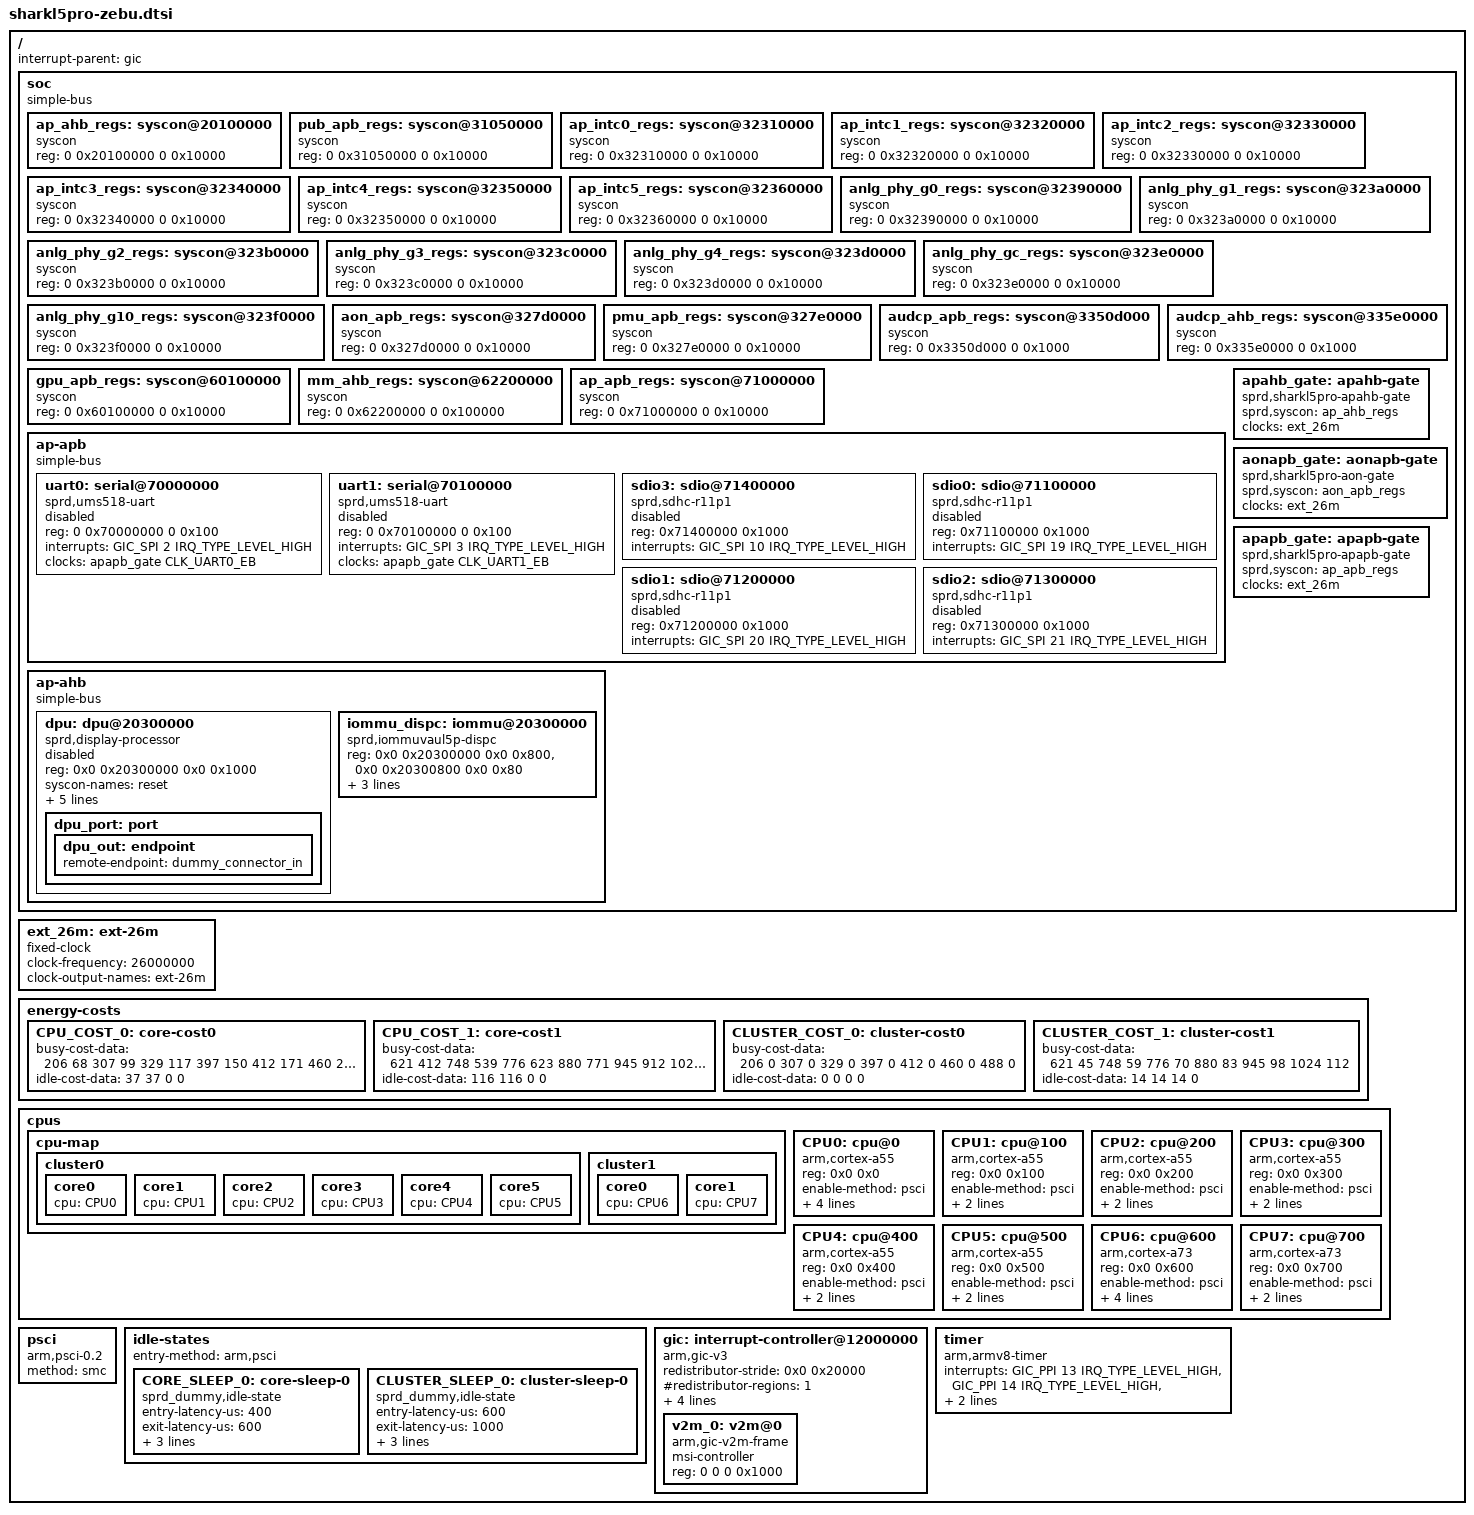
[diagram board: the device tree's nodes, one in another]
// SPDX-License-Identifier: (GPL-2.0+ OR MIT)
/*
 * Unisoc Sharkl5Pro platform DTS file
 *
 * Copyright (C) 2018, Unisoc Communications Inc.
 */

#include <dt-bindings/soc/sprd,sharkl5pro-regs.h>
#include <dt-bindings/soc/sprd,sharkl5pro-mask.h>
#include <dt-bindings/clock/sprd,sharkl5pro-clk.h>
#include <dt-bindings/interrupt-controller/arm-gic.h>

/ {
	interrupt-parent = <&gic>;
	#address-cells = <2>;
	#size-cells = <2>;

	soc: soc {
		compatible = "simple-bus";
		#address-cells = <2>;
		#size-cells = <2>;
		ranges;

		ap_ahb_regs: syscon@20100000 {
			compatible = "syscon";
			#syscon-cells = <2>;
			reg = <0 0x20100000 0 0x10000>;
		};

		pub_apb_regs: syscon@31050000 {
			compatible = "syscon";
			#syscon-cells = <2>;
			reg = <0 0x31050000 0 0x10000>;
		};

		ap_intc0_regs: syscon@32310000 {
			compatible = "syscon";
			#syscon-cells = <2>;
			reg = <0 0x32310000 0 0x10000>;
		};

		ap_intc1_regs: syscon@32320000 {
			compatible = "syscon";
			#syscon-cells = <2>;
			reg = <0 0x32320000 0 0x10000>;
		};

		ap_intc2_regs: syscon@32330000 {
			compatible = "syscon";
			#syscon-cells = <2>;
			reg = <0 0x32330000 0 0x10000>;
		};

		ap_intc3_regs: syscon@32340000 {
			compatible = "syscon";
			#syscon-cells = <2>;
			reg = <0 0x32340000 0 0x10000>;
		};

		ap_intc4_regs: syscon@32350000 {
			compatible = "syscon";
			#syscon-cells = <2>;
			reg = <0 0x32350000 0 0x10000>;
		};

		ap_intc5_regs: syscon@32360000 {
			compatible = "syscon";
			#syscon-cells = <2>;
			reg = <0 0x32360000 0 0x10000>;
		};

		anlg_phy_g0_regs: syscon@32390000 {
			compatible = "syscon";
			#syscon-cells = <2>;
			reg = <0 0x32390000 0 0x10000>;
		};

		anlg_phy_g1_regs: syscon@323a0000 {
			compatible = "syscon";
			#syscon-cells = <2>;
			reg = <0 0x323a0000 0 0x10000>;
		};

		anlg_phy_g2_regs: syscon@323b0000 {
			compatible = "syscon";
			#syscon-cells = <2>;
			reg = <0 0x323b0000 0 0x10000>;
		};

		anlg_phy_g3_regs: syscon@323c0000 {
			compatible = "syscon";
			#syscon-cells = <2>;
			reg = <0 0x323c0000 0 0x10000>;
		};

		anlg_phy_g4_regs: syscon@323d0000 {
			compatible = "syscon";
			#syscon-cells = <2>;
			reg = <0 0x323d0000 0 0x10000>;
		};

		anlg_phy_gc_regs: syscon@323e0000 {
			compatible = "syscon";
			#syscon-cells = <2>;
			reg = <0 0x323e0000 0 0x10000>;
		};

		anlg_phy_g10_regs: syscon@323f0000 {
			compatible = "syscon";
			#syscon-cells = <2>;
			reg = <0 0x323f0000 0 0x10000>;
		};

		aon_apb_regs: syscon@327d0000 {
			compatible = "syscon";
			#syscon-cells = <2>;
			reg = <0 0x327d0000 0 0x10000>;
		};

		pmu_apb_regs: syscon@327e0000 {
			compatible = "syscon";
			#syscon-cells = <2>;
			reg = <0 0x327e0000 0 0x10000>;
		};

		audcp_apb_regs: syscon@3350d000 {
			compatible = "syscon";
			#syscon-cells = <2>;
			reg = <0 0x3350d000 0 0x1000>;
		};

		audcp_ahb_regs: syscon@335e0000 {
			compatible = "syscon";
			#syscon-cells = <2>;
			reg = <0 0x335e0000 0 0x1000>;
		};

		gpu_apb_regs: syscon@60100000 {
			compatible = "syscon";
			#syscon-cells = <2>;
			reg = <0 0x60100000 0 0x10000>;
		};

		mm_ahb_regs: syscon@62200000 {
			compatible = "syscon";
			#syscon-cells = <2>;
			reg = <0 0x62200000 0 0x100000>;
		};

		ap_apb_regs: syscon@71000000 {
			compatible = "syscon";
			#syscon-cells = <2>;
			reg = <0 0x71000000 0 0x10000>;
		};

		ap-apb {
			compatible = "simple-bus";
			#address-cells = <2>;
			#size-cells = <2>;
			ranges;

			uart0: serial@70000000 {
				compatible = "sprd,ums518-uart",
					     "sprd,sc9836-uart";
				reg = <0 0x70000000 0 0x100>;
				interrupts = <GIC_SPI 2 IRQ_TYPE_LEVEL_HIGH>;
				clock-names = "enable", "uart", "source";
				clocks = <&apapb_gate CLK_UART0_EB>;
				status = "disabled";
			};

			uart1: serial@70100000 {
				compatible = "sprd,ums518-uart",
					     "sprd,sc9836-uart";
				reg = <0 0x70100000 0 0x100>;
				interrupts = <GIC_SPI 3 IRQ_TYPE_LEVEL_HIGH>;
				clock-names = "enable", "uart", "source";
				clocks = <&apapb_gate CLK_UART1_EB>;
				status = "disabled";
			};

			sdio3: sdio@71400000 {
				compatible = "sprd,sdhc-r11p1";
				reg = <0x71400000  0x1000>;
				interrupts = <GIC_SPI 10 IRQ_TYPE_LEVEL_HIGH>;
				status = "disabled";
			};

			sdio0: sdio@71100000 {
				compatible = "sprd,sdhc-r11p1";
				reg = <0x71100000 0x1000>;
				interrupts = <GIC_SPI 19 IRQ_TYPE_LEVEL_HIGH>;
				status = "disabled";
			};

			sdio1: sdio@71200000 {
				compatible = "sprd,sdhc-r11p1";
				reg = <0x71200000 0x1000>;
				interrupts = <GIC_SPI 20 IRQ_TYPE_LEVEL_HIGH>;
				status = "disabled";
			};

			sdio2: sdio@71300000 {
				compatible = "sprd,sdhc-r11p1";
				reg = <0x71300000 0x1000>;
				interrupts = <GIC_SPI 21 IRQ_TYPE_LEVEL_HIGH>;
				status = "disabled";
			};
		};

		ap-ahb {
			compatible = "simple-bus";
			#address-cells = <2>;
			#size-cells = <2>;
			ranges;

			dpu: dpu@20300000 {
				compatible = "sprd,display-processor";
				reg = <0x0 0x20300000 0x0 0x1000>;
				/*syscons = <&ap_ahb_regs REG_AP_AHB_AHB_RST
					MASK_AP_AHB_DISPC_SOFT_RST>;*/
				syscon-names = "reset";
				interrupts = <GIC_SPI 27 IRQ_TYPE_LEVEL_HIGH>;
				status = "disabled";
				iommus = <&iommu_dispc>;

				dma-coherent;

				sprd,ip = "dpu-r4p0";
				sprd,soc = "sharkl5Pro";

				dpu_port: port {
					dpu_out: endpoint {
						remote-endpoint = <&dummy_connector_in>;
					};
				};
			};

			iommu_dispc: iommu@20300000 {
				compatible = "sprd,iommuvaul5p-dispc";
				reg = <0x0 0x20300000 0x0 0x800>,
				      <0x0 0x20300800 0x0 0x80>;
				iova-base = <0x30000000>;
				iova-size = <0x10000000>;
				reg_name = "mmu_interrupt_reg","mmu_reg";
				status = "okay";
				#iommu-cells = <0>;
			};
		};

		apahb_gate: apahb-gate {
			compatible = "sprd,sharkl5pro-apahb-gate";
			sprd,syscon = <&ap_ahb_regs>; /* 0x20100000 */
			clocks = <&ext_26m>;
			#clock-cells = <1>;
		};

		aonapb_gate: aonapb-gate {
			compatible = "sprd,sharkl5pro-aon-gate";
			sprd,syscon = <&aon_apb_regs>; /* 0x327d0000 */
			clocks = <&ext_26m>;
			#clock-cells = <1>;
		};

		apapb_gate: apapb-gate {
			compatible = "sprd,sharkl5pro-apapb-gate";
			sprd,syscon = <&ap_apb_regs>; /* 0x71000000 */
			clocks = <&ext_26m>;
			#clock-cells = <1>;
		};
	};

	ext_26m: ext-26m {
		compatible = "fixed-clock";
		#clock-cells = <0>;
		clock-frequency = <26000000>;
		clock-output-names = "ext-26m";
	};

	energy-costs {
		CPU_COST_0: core-cost0 {
			busy-cost-data = <
				206 68
				307 99
				329 117
				397 150
				412 171
				460 207
				488 241
			>;
			idle-cost-data = <
				37		/* ACTIVE-IDLE */
				37
				0
				0
			>;
		};
		CPU_COST_1: core-cost1 {
			busy-cost-data = <
				621 412
				748 539
				776 623
				880 771
				945 912
				1024 1083
			>;
			idle-cost-data = <
				116		// ACTIVE-IDLE
				116
				0
				0
			>;
		};
		CLUSTER_COST_0: cluster-cost0 {
			busy-cost-data = <
				206 0
				307 0
				329 0
				397 0
				412 0
				460 0
				488 0
			>;
			idle-cost-data = <
				0		// ACTIVE-IDLE
				0
				0
				0
			>;
		};
		CLUSTER_COST_1: cluster-cost1 {
			busy-cost-data = <
				621 45
				748 59
				776 70
				880 83
				945 98
				1024 112
			>;
			idle-cost-data = <
				14		// ACTIVE-IDLE
				14
				14
				0
			>;
		};
	};

	cpus {
		#address-cells = <2>;
		#size-cells = <0>;

		cpu-map {
			cluster0 {
				core0 {
					cpu = <&CPU0>;
				};
				core1 {
					cpu = <&CPU1>;
				};
				core2 {
					cpu = <&CPU2>;
				};
				core3 {
					cpu = <&CPU3>;
				};
				core4 {
					cpu = <&CPU4>;
				};
				core5 {
					cpu = <&CPU5>;
				};
			};
			cluster1 {
				core0 {
					cpu = <&CPU6>;
				};
				core1 {
					cpu = <&CPU7>;
				};
			};
		};

		CPU0: cpu@0 {
			device_type = "cpu";
			compatible = "arm,cortex-a55","arm,armv8";
			reg = <0x0 0x0>;
			enable-method = "psci";
			cpu-idle-states = <&CORE_SLEEP_0 &CLUSTER_SLEEP_0>;
			sched-energy-costs = <&CPU_COST_0 &CLUSTER_COST_0>;
			operating-points = <
				1820000	1000000
				1716000 950000
				1536000 900000
				1482000 850000
				1228000 800000
				1144000 750000
				768000  700000
			>;
		};
		CPU1: cpu@100 {
			device_type = "cpu";
			compatible = "arm,cortex-a55","arm,armv8";
			reg = <0x0 0x100>;
			enable-method = "psci";
			cpu-idle-states = <&CORE_SLEEP_0 &CLUSTER_SLEEP_0>;
			sched-energy-costs = <&CPU_COST_0 &CLUSTER_COST_0>;
		};
		CPU2: cpu@200 {
			device_type = "cpu";
			compatible = "arm,cortex-a55","arm,armv8";
			reg = <0x0 0x200>;
			enable-method = "psci";
			cpu-idle-states = <&CORE_SLEEP_0 &CLUSTER_SLEEP_0>;
			sched-energy-costs = <&CPU_COST_0 &CLUSTER_COST_0>;
		};
		CPU3: cpu@300 {
			device_type = "cpu";
			compatible = "arm,cortex-a55","arm,armv8";
			reg = <0x0 0x300>;
			enable-method = "psci";
			cpu-idle-states = <&CORE_SLEEP_0 &CLUSTER_SLEEP_0>;
			sched-energy-costs = <&CPU_COST_0 &CLUSTER_COST_0>;
		};
		CPU4: cpu@400 {
			device_type = "cpu";
			compatible = "arm,cortex-a55","arm,armv8";
			reg = <0x0 0x400>;
			enable-method = "psci";
			cpu-idle-states = <&CORE_SLEEP_0 &CLUSTER_SLEEP_0>;
			sched-energy-costs = <&CPU_COST_0 &CLUSTER_COST_0>;
		};
		CPU5: cpu@500 {
			device_type = "cpu";
			compatible = "arm,cortex-a55","arm,armv8";
			reg = <0x0 0x500>;
			enable-method = "psci";
			cpu-idle-states = <&CORE_SLEEP_0 &CLUSTER_SLEEP_0>;
			sched-energy-costs = <&CPU_COST_0 &CLUSTER_COST_0>;
		};
		CPU6: cpu@600 {
			device_type = "cpu";
			compatible = "arm,cortex-a73","arm,armv8";
			reg = <0x0 0x600>;
			enable-method = "psci";
			cpu-idle-states = <&CORE_SLEEP_0 &CLUSTER_SLEEP_0>;
			sched-energy-costs = <&CPU_COST_1 &CLUSTER_COST_1>;
			operating-points = <
				2028000	1000000
				1872000 950000
				1742000 900000
				1536000 850000
				1482000 800000
				1229000 750000
			>;
		};
		CPU7: cpu@700 {
			device_type = "cpu";
			compatible = "arm,cortex-a73","arm,armv8";
			reg = <0x0 0x700>;
			enable-method = "psci";
			cpu-idle-states = <&CORE_SLEEP_0 &CLUSTER_SLEEP_0>;
			sched-energy-costs = <&CPU_COST_1 &CLUSTER_COST_1>;
		};
	};

	psci {
		compatible = "arm,psci-0.2";
		method = "smc";
	};

	idle-states {
		entry-method = "arm,psci";
		CORE_SLEEP_0: core-sleep-0 {
			compatible = "sprd_dummy,idle-state";
			entry-latency-us = <400>;
			exit-latency-us = <600>;
			min-residency-us = <1800>;
			local-timer-stop;
			arm,psci-suspend-param = <0x00010000>;
		};
		CLUSTER_SLEEP_0: cluster-sleep-0 {
			compatible = "sprd_dummy,idle-state";
			entry-latency-us = <600>;
			exit-latency-us = <1000>;
			min-residency-us = <2800>;
			local-timer-stop;
			arm,psci-suspend-param = <0x01010000>;
		};
	};

	gic: interrupt-controller@12000000 {
		compatible = "arm,gic-v3";
		#interrupt-cells = <3>;
		#address-cells = <2>;
		#size-cells = <2>;
		ranges;
		redistributor-stride = <0x0 0x20000>;	/* 128KB stride */
		#redistributor-regions = <1>;
		interrupt-controller;
		reg = <0x0 0x12000000 0 0x20000>,	/* GICD */
			<0x0 0x12040000 0 0x100000>;	/* GICR */
		interrupts = <1 9 4>;
		v2m_0: v2m@0 {
			compatible = "arm,gic-v2m-frame";
			msi-controller;
			reg = <0 0 0 0x1000>;
		};
	};

	timer {
		compatible = "arm,armv8-timer";
		interrupts = <GIC_PPI 13 IRQ_TYPE_LEVEL_HIGH>, /* Physical Secure PPI */
			<GIC_PPI 14 IRQ_TYPE_LEVEL_HIGH>, /* Physical Non-Secure PPI */
			<GIC_PPI 11 IRQ_TYPE_LEVEL_HIGH>, /* Virtual PPI */
			<GIC_PPI 10 IRQ_TYPE_LEVEL_HIGH>; /* Hipervisor PPI */
	};
};
